# SAM9X75D5M device description
Architecture: ARM926EJ-S; Family: SAM9; Series: SAM9X7
Registers are 32-bit, read-write, reset 0x0 unless marked. A register's access mark holds for its fields unless they carry their own. Offsets are from the block's base; [hi:lo] are bit positions.

## RTT — Real-time Timer
Instances: RTT 0xFFFFFE20
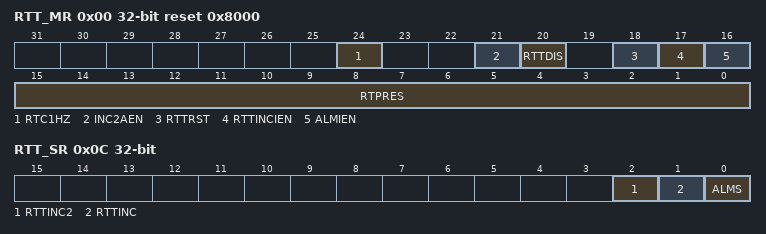
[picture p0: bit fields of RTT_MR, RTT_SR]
0x00 RTT_MR reset 0x8000 — Mode Register
  [24] RTC1HZ — Real-Time Clock 1Hz Clock Selection
    0=The RTT 32-bit counter is driven by the 16-bit prescaler roll-over events; 1=The RTT 32-bit counter is driven by the 1Hz RTC clock
  [21] INC2AEN — RTTINC2 Alarm and Interrupt Enable
    0=The RTTINC2 flag is not a source of the RTT alarm signal nor a source of interrupt; 1=The RTTINC2 flag is a source of the RTT alarm signal and a source of interrupt
  [20] RTTDIS — Real-time Timer Disable
    0=The real-time timer is enabled; 1=The real-time timer is disabled (no dynamic power consumption)
  [18] RTTRST — Real-time Timer Restart
    0=No effect; 1=Reloads and restarts the clock divider with the new programmed value. This also resets the 32-bit counter.
  [17] RTTINCIEN — Real-time Timer Increment Interrupt Enable
    0=The bit RTTINC in RTT_SR has no effect on interrupt; 1=The bit RTTINC in RTT_SR asserts interrupt
  [16] ALMIEN — Alarm Interrupt Enable
    0=The bit ALMS in RTT_SR has no effect on interrupt; 1=The bit ALMS in RTT_SR asserts interrupt
  [15:0] RTPRES — Real-time Timer Prescaler Value
0x04 RTT_AR reset 0xFFFFFFFF — Alarm Register
  [31:0] ALMV — Alarm Value
0x08 RTT_VR ro — Value Register
  [31:0] CRTV — Current Real-time Value
0x0C RTT_SR ro — Status Register
  [2] RTTINC2 — Predefined Number of Prescaler Roll-overs Status (cleared on read)
    0=SELINC2=0 or the number of prescaler roll-overs programmed through the SELINC2 field in RTT_MODR has not been reached since the last read of the RTT_SR; 1=The number of prescaler roll-overs programmed through the SELINC2 field has been reached since the last read of the RTT_SR
  [1] RTTINC — Prescaler Roll-over Status (cleared on read)
    0=No prescaler roll-over occurred since the last read of the RTT_SR; 1=Prescaler roll-over occurred since the last read of the RTT_SR
  [0] ALMS — Real-time Alarm Status (cleared on read)
    0=The Real-time Alarm has not occurred since the last read of RTT_SR; 1=The Real-time Alarm occurred since the last read of RTT_SR
0x10 RTT_MODR — Modulo Selection Register
  [2:0] SELINC2 — Selection of the 32-bit Counter Modulo to generate RTTINC2 Flag
    0=NO_RTTINC2 (The RTTINC2 flag never rises); 1=MOD64 (The RTTINC2 flag is set when CRTV modulo 64 equals 0); 2=MOD128 (The RTTINC2 flag is set when CRTV modulo 128 equals 0); 3=MOD256 (The RTTINC2 flag is set when CRTV modulo 256 equals 0); 4=MOD512 (The RTTINC2 flag is set when CRTV modulo 512 equals 0); 5=MOD1024 (The RTTINC2 flag is set when CRTV modulo 1024 equals 0. Example: If RTPRES=32 then RTTINC2 flag rises once per second if the slow clock is 32.768 kHz.); 6=MOD2048 (The RTTINC2 flag is set when CRTV modulo 2048 equals 0); 7=MOD4096 (The RTTINC2 flag is set when CRTV modulo 4096 equals 0)
0x14 RTT_TSR ro — TimeStamp Register
  [23:0] TSTAMP — Real-time Timer Value Timestamp

## SCKC — Slow Clock Controller
Instances: SCKC 0xFFFFFE50
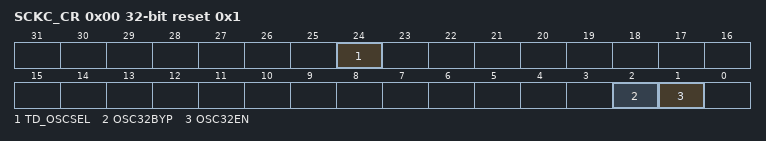
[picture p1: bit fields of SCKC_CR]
0x00 SCKC_CR reset 0x1 — Slow Clock Controller Configuration Register
  [24] TD_OSCSEL — Timing Domain Slow Clock Selector
    0=RC (Slow clock of the timing domain is driven by the embedded 32 kHz (typical) RC oscillator.); 1=XTAL (Slow clock of the timing domain is driven by the 32.768 kHz crystal oscillator.)
  [2] OSC32BYP — 32.768 kHz Crystal Oscillator Bypass
    0=32.768 kHz crystal oscillator is not bypassed; 1=32.768 kHz crystal oscillator is bypassed and accepts an external slow clock on XIN32
  [1] OSC32EN — 32.768 kHz Crystal Oscillator
    0=32.768 kHz crystal oscillator is disabled; 1=32.768 kHz crystal oscillator is enabled

## SHDWC — Shutdown Controller
Instances: SHDWC 0xFFFFFE10
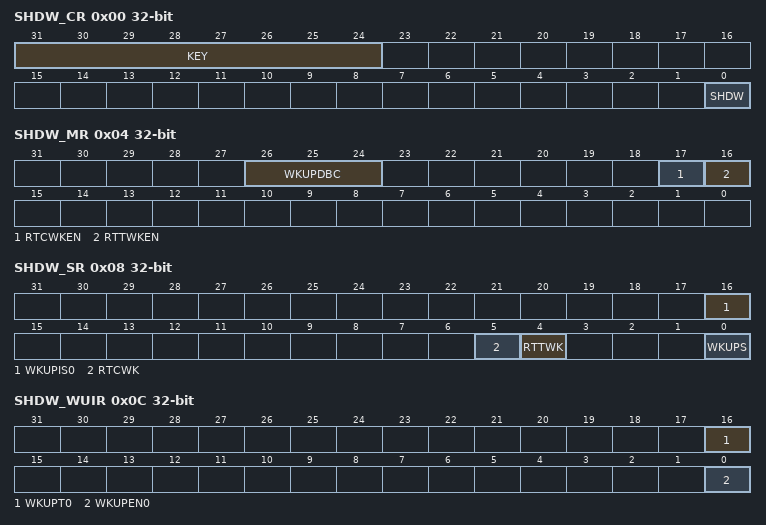
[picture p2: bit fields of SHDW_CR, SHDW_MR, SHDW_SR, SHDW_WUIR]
0x00 SHDW_CR wo reset not defined — Control Register
  [31:24] KEY — Password
    165=PASSWD (Writing any other value in this field aborts the write operation.)
  [0] SHDW — Shutdown Command
    0=No effect; 1=If KEY value is correct, asserts the SHDN pin
0x04 SHDW_MR — Mode Register
  [26:24] WKUPDBC — Wakeup Inputs Debouncer Period
    0=IMMEDIATE (Immediate, no debouncing, detected active at least on one MD_SLCK edge.); 1=3_SLCK (WKUP shall be in its active state for at least 3 MD_SLCK periods); 2=32_SLCK (WKUP shall be in its active state for at least 32 MD_SLCK periods); 3=512_SLCK (WKUP shall be in its active state for at least 512 MD_SLCK periods); 4=4096_SLCK (WKUP shall be in its active state for at least 4,096 MD_SLCK periods); 5=32768_SLCK (WKUP shall be in its active state for at least 32,768 MD_SLCK periods)
  [17] RTCWKEN — Real-time Clock Wakeup Enable
    0=The RTC Alarm signal has no effect on the Shutdown Controller; 1=The RTC Alarm signal forces the de-assertion of the SHDN pin
  [16] RTTWKEN — Real-time Timer Wakeup Enable
    0=The RTT Alarm signal has no effect on the Shutdown Controller; 1=The RTT Alarm signal forces the de-assertion of the SHDN pin
0x08 SHDW_SR ro — Status Register
  [16] WKUPIS0 — Wakeup 0 Input Status
    0=DISABLE (The wakeup 0 input is disabled, or was inactive at the time the debouncer triggered a wakeup event.); 1=ENABLE (The wakeup 0 input was active at the time the debouncer triggered a wakeup event.)
  [5] RTCWK — Real-time Clock Wakeup
    0=No wakeup alarm from the RTC occurred since the last read of SHDW_SR; 1=At least one wakeup alarm from the RTC occurred since the last read of SHDW_SR
  [4] RTTWK — Real-time Timer Wakeup
    0=No wakeup alarm from the RTT occurred since the last read of SHDW_SR; 1=At least one wakeup alarm from the RTT occurred since the last read of SHDW_SR
  [0] WKUPS — WKUP Wakeup Status
    0=NO (No wakeup due to the assertion of the WKUP pin has occurred since the last read of SHDW_SR.); 1=PRESENT (At least one wakeup due to the assertion of the WKUP pin has occurred since the last read of SHDW_SR.)
0x0C SHDW_WUIR — Wakeup Inputs Register
  [16] WKUPT0 — Wakeup 0 Input Type
    0=LOW (A falling edge followed by a low level on the wakeup 0 input, for a period defined by WKUPDBC, forces wakeup of the core power supply.); 1=HIGH (A rising edge followed by a high level on the wakeup 0 input, for a period defined by WKUPDBC, forces wakeup of the core power supply.)
  [0] WKUPEN0 — Wakeup 0 Input Enable
    0=DISABLE (The wakeup 0 input has no wakeup effect.); 1=ENABLE (The wakeup 0 input forces wakeup of the core power supply.)
